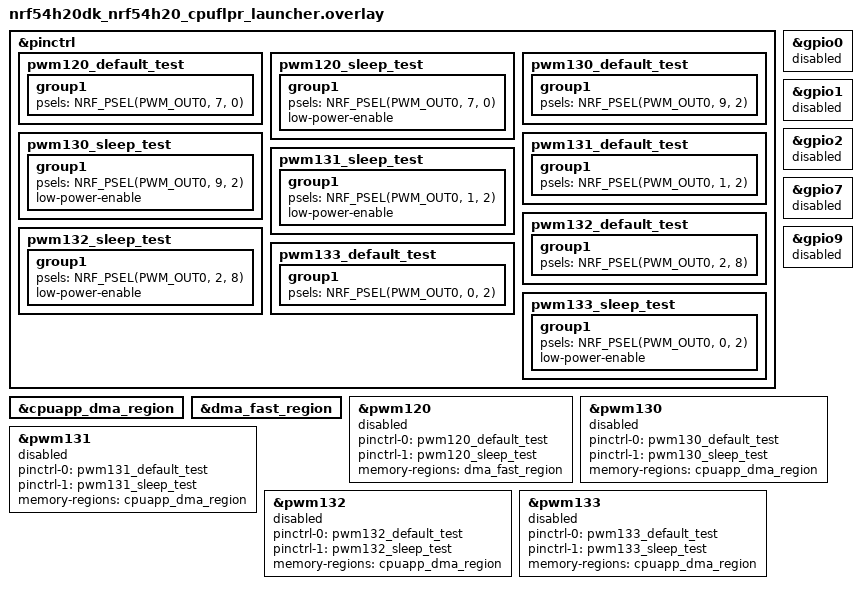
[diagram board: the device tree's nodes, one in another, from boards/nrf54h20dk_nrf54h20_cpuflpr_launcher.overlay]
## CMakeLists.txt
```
# SPDX-License-Identifier: LicenseRef-Nordic-5-Clause

cmake_minimum_required(VERSION 3.20.0)

find_package(Zephyr REQUIRED HINTS $ENV{ZEPHYR_BASE})
project(pwm_instances)

FILE(GLOB app_sources src/*.c)
target_sources(app PRIVATE ${app_sources})
```

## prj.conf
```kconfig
CONFIG_ZTEST=y
CONFIG_TEST_USERSPACE=y
CONFIG_PWM=y
CONFIG_LOG=y
```

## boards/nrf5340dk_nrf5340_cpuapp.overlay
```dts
/*
 * Copyright (c) 2026 Nordic Semiconductor ASA
 *
 * SPDX-License-Identifier: LicenseRef-Nordic-5-Clause
 */

&pinctrl {
	pwm0_default_test: pwm0_default_test {
		group1 {
			psels = <NRF_PSEL(PWM_OUT0, 0, 4)>;
		};
	};

	pwm0_sleep_test: pwm0_sleep_test {
		group1 {
			psels = <NRF_PSEL(PWM_OUT0, 0, 6)>;
			low-power-enable;
		};
	};

	pwm1_default_test: pwm1_default_test {
		group1 {
			psels = <NRF_PSEL(PWM_OUT0, 1, 4)>;
		};
	};

	pwm1_sleep_test: pwm1_sleep_test {
		group1 {
			psels = <NRF_PSEL(PWM_OUT0, 1, 4)>;
			low-power-enable;
		};
	};

	pwm2_default_test: pwm2_default_test {
		group1 {
			psels = <NRF_PSEL(PWM_OUT0, 1, 6)>;
		};
	};

	pwm2_sleep_test: pwm2_sleep_test {
		group1 {
			psels = <NRF_PSEL(PWM_OUT0, 1, 6)>;
			low-power-enable;
		};
	};

	pwm3_default_test: pwm3_default_test {
		group1 {
			psels = <NRF_PSEL(PWM_OUT0, 1, 8)>;
		};
	};

	pwm3_sleep_test: pwm3_sleep_test {
		group1 {
			psels = <NRF_PSEL(PWM_OUT0, 1, 8)>;
			low-power-enable;
		};
	};
};

&pwm0 {
	status = "okay";
	pinctrl-0 = <&pwm0_default_test>;
	pinctrl-1 = <&pwm0_sleep_test>;
	pinctrl-names = "default", "sleep";
};

&pwm1 {
	status = "okay";
	pinctrl-0 = <&pwm1_default_test>;
	pinctrl-1 = <&pwm1_sleep_test>;
	pinctrl-names = "default", "sleep";
};

&pwm2 {
	status = "okay";
	pinctrl-0 = <&pwm2_default_test>;
	pinctrl-1 = <&pwm2_sleep_test>;
	pinctrl-names = "default", "sleep";
};

&pwm3 {
	status = "okay";
	pinctrl-0 = <&pwm3_default_test>;
	pinctrl-1 = <&pwm3_sleep_test>;
	pinctrl-names = "default", "sleep";
};
```

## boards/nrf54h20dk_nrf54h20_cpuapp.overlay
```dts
/*
 * Copyright (c) 2025 Nordic Semiconductor ASA
 *
 * SPDX-License-Identifier: LicenseRef-Nordic-5-Clause
 */

&pinctrl {
	pwm120_default_test: pwm120_default_test {
		group1 {
			psels = <NRF_PSEL(PWM_OUT0, 7, 0)>;
		};
	};

	pwm120_sleep_test: pwm120_sleep_test {
		group1 {
			psels = <NRF_PSEL(PWM_OUT0, 7, 0)>;
			low-power-enable;
		};
	};

	pwm130_default_test: pwm130_default_test {
		group1 {
			psels = <NRF_PSEL(PWM_OUT0, 9, 2)>;
		};
	};

	pwm130_sleep_test: pwm130_sleep_test {
		group1 {
			psels = <NRF_PSEL(PWM_OUT0, 9, 2)>;
			low-power-enable;
		};
	};

	pwm131_default_test: pwm131_default_test {
		group1 {
			psels = <NRF_PSEL(PWM_OUT0, 1, 2)>;
		};
	};

	pwm131_sleep_test: pwm131_sleep_test {
		group1 {
			psels = <NRF_PSEL(PWM_OUT0, 1, 2)>;
			low-power-enable;
		};
	};

	pwm132_default_test: pwm132_default_test {
		group1 {
			psels = <NRF_PSEL(PWM_OUT0, 2, 8)>;
		};
	};

	pwm132_sleep_test: pwm132_sleep_test {
		group1 {
			psels = <NRF_PSEL(PWM_OUT0, 2, 8)>;
			low-power-enable;
		};
	};

	pwm133_default_test: pwm133_default_test {
		group1 {
			psels = <NRF_PSEL(PWM_OUT0, 0, 2)>;
		};
	};

	pwm133_sleep_test: pwm133_sleep_test {
		group1 {
			psels = <NRF_PSEL(PWM_OUT0, 0, 2)>;
			low-power-enable;
		};
	};
};

&pwm120 {
	status = "okay";
	pinctrl-0 = <&pwm120_default_test>;
	pinctrl-1 = <&pwm120_sleep_test>;
	pinctrl-names = "default", "sleep";
	memory-regions = <&dma_fast_region>;
};

&dma_fast_region {
	status = "okay";
};

&pwm130 {
	status = "okay";
	pinctrl-0 = <&pwm130_default_test>;
	pinctrl-1 = <&pwm130_sleep_test>;
	pinctrl-names = "default", "sleep";
	memory-regions = <&cpuapp_dma_region>;
};

&pwm131 {
	status = "okay";
	pinctrl-0 = <&pwm131_default_test>;
	pinctrl-1 = <&pwm131_sleep_test>;
	pinctrl-names = "default", "sleep";
	memory-regions = <&cpuapp_dma_region>;
};

&pwm132 {
	status = "okay";
	pinctrl-0 = <&pwm132_default_test>;
	pinctrl-1 = <&pwm132_sleep_test>;
	pinctrl-names = "default", "sleep";
	memory-regions = <&cpuapp_dma_region>;
};

&pwm133 {
	status = "okay";
	pinctrl-0 = <&pwm133_default_test>;
	pinctrl-1 = <&pwm133_sleep_test>;
	pinctrl-names = "default", "sleep";
	memory-regions = <&cpuapp_dma_region>;
};
```

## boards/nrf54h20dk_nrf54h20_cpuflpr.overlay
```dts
/*
 * Copyright (c) 2026 Nordic Semiconductor ASA
 *
 * SPDX-License-Identifier: LicenseRef-Nordic-5-Clause
 */

/*
 * Same PWM instances and pinout as nrf54h20dk_nrf54h20_cpuapp.overlay.
 * PWM120 uses dma_fast_region; PWM130–133 use cpuapp_dma_region (enabled below).
 */

&pinctrl {
	pwm120_default_test: pwm120_default_test {
		group1 {
			psels = <NRF_PSEL(PWM_OUT0, 7, 0)>;
		};
	};

	pwm120_sleep_test: pwm120_sleep_test {
		group1 {
			psels = <NRF_PSEL(PWM_OUT0, 7, 0)>;
			low-power-enable;
		};
	};

	pwm130_default_test: pwm130_default_test {
		group1 {
			psels = <NRF_PSEL(PWM_OUT0, 9, 2)>;
		};
	};

	pwm130_sleep_test: pwm130_sleep_test {
		group1 {
			psels = <NRF_PSEL(PWM_OUT0, 9, 2)>;
			low-power-enable;
		};
	};

	pwm131_default_test: pwm131_default_test {
		group1 {
			psels = <NRF_PSEL(PWM_OUT0, 1, 2)>;
		};
	};

	pwm131_sleep_test: pwm131_sleep_test {
		group1 {
			psels = <NRF_PSEL(PWM_OUT0, 1, 2)>;
			low-power-enable;
		};
	};

	pwm132_default_test: pwm132_default_test {
		group1 {
			psels = <NRF_PSEL(PWM_OUT0, 2, 8)>;
		};
	};

	pwm132_sleep_test: pwm132_sleep_test {
		group1 {
			psels = <NRF_PSEL(PWM_OUT0, 2, 8)>;
			low-power-enable;
		};
	};

	pwm133_default_test: pwm133_default_test {
		group1 {
			psels = <NRF_PSEL(PWM_OUT0, 0, 2)>;
		};
	};

	pwm133_sleep_test: pwm133_sleep_test {
		group1 {
			psels = <NRF_PSEL(PWM_OUT0, 0, 2)>;
			low-power-enable;
		};
	};
};

&cpuapp_dma_region {
	status = "okay";
};

&dma_fast_region {
	status = "okay";
};

&pwm120 {
	status = "okay";
	pinctrl-0 = <&pwm120_default_test>;
	pinctrl-1 = <&pwm120_sleep_test>;
	pinctrl-names = "default", "sleep";
	memory-regions = <&dma_fast_region>;
};

&pwm130 {
	status = "okay";
	pinctrl-0 = <&pwm130_default_test>;
	pinctrl-1 = <&pwm130_sleep_test>;
	pinctrl-names = "default", "sleep";
	memory-regions = <&cpuapp_dma_region>;
};

&pwm131 {
	status = "okay";
	pinctrl-0 = <&pwm131_default_test>;
	pinctrl-1 = <&pwm131_sleep_test>;
	pinctrl-names = "default", "sleep";
	memory-regions = <&cpuapp_dma_region>;
};

&pwm132 {
	status = "okay";
	pinctrl-0 = <&pwm132_default_test>;
	pinctrl-1 = <&pwm132_sleep_test>;
	pinctrl-names = "default", "sleep";
	memory-regions = <&cpuapp_dma_region>;
};

&pwm133 {
	status = "okay";
	pinctrl-0 = <&pwm133_default_test>;
	pinctrl-1 = <&pwm133_sleep_test>;
	pinctrl-names = "default", "sleep";
	memory-regions = <&cpuapp_dma_region>;
};
```

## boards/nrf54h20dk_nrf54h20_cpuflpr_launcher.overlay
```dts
/*
 * Copyright (c) 2026 Nordic Semiconductor ASA
 *
 * SPDX-License-Identifier: LicenseRef-Nordic-5-Clause
 */

/*
 * vpr_launcher (cpuapp): reserve all PWM instances and pads used by the FLPR
 * pwm_instances image (same mapping as cpuapp overlay).
 */

&pinctrl {
	pwm120_default_test: pwm120_default_test {
		group1 {
			psels = <NRF_PSEL(PWM_OUT0, 7, 0)>;
		};
	};

	pwm120_sleep_test: pwm120_sleep_test {
		group1 {
			psels = <NRF_PSEL(PWM_OUT0, 7, 0)>;
			low-power-enable;
		};
	};

	pwm130_default_test: pwm130_default_test {
		group1 {
			psels = <NRF_PSEL(PWM_OUT0, 9, 2)>;
		};
	};

	pwm130_sleep_test: pwm130_sleep_test {
		group1 {
			psels = <NRF_PSEL(PWM_OUT0, 9, 2)>;
			low-power-enable;
		};
	};

	pwm131_default_test: pwm131_default_test {
		group1 {
			psels = <NRF_PSEL(PWM_OUT0, 1, 2)>;
		};
	};

	pwm131_sleep_test: pwm131_sleep_test {
		group1 {
			psels = <NRF_PSEL(PWM_OUT0, 1, 2)>;
			low-power-enable;
		};
	};

	pwm132_default_test: pwm132_default_test {
		group1 {
			psels = <NRF_PSEL(PWM_OUT0, 2, 8)>;
		};
	};

	pwm132_sleep_test: pwm132_sleep_test {
		group1 {
			psels = <NRF_PSEL(PWM_OUT0, 2, 8)>;
			low-power-enable;
		};
	};

	pwm133_default_test: pwm133_default_test {
		group1 {
			psels = <NRF_PSEL(PWM_OUT0, 0, 2)>;
		};
	};

	pwm133_sleep_test: pwm133_sleep_test {
		group1 {
			psels = <NRF_PSEL(PWM_OUT0, 0, 2)>;
			low-power-enable;
		};
	};
};

&gpio0 {
	status = "reserved";
};

&gpio1 {
	status = "reserved";
};

&gpio2 {
	status = "reserved";
};

&gpio7 {
	status = "reserved";
};

&gpio9 {
	status = "reserved";
};

&cpuapp_dma_region {
	status = "okay";
};

&dma_fast_region {
	status = "okay";
};

&pwm120 {
	status = "reserved";
	pinctrl-0 = <&pwm120_default_test>;
	pinctrl-1 = <&pwm120_sleep_test>;
	pinctrl-names = "default", "sleep";
	memory-regions = <&dma_fast_region>;
};

&pwm130 {
	status = "reserved";
	pinctrl-0 = <&pwm130_default_test>;
	pinctrl-1 = <&pwm130_sleep_test>;
	pinctrl-names = "default", "sleep";
	memory-regions = <&cpuapp_dma_region>;
};

&pwm131 {
	status = "reserved";
	pinctrl-0 = <&pwm131_default_test>;
	pinctrl-1 = <&pwm131_sleep_test>;
	pinctrl-names = "default", "sleep";
	memory-regions = <&cpuapp_dma_region>;
};

&pwm132 {
	status = "reserved";
	pinctrl-0 = <&pwm132_default_test>;
	pinctrl-1 = <&pwm132_sleep_test>;
	pinctrl-names = "default", "sleep";
	memory-regions = <&cpuapp_dma_region>;
};

&pwm133 {
	status = "reserved";
	pinctrl-0 = <&pwm133_default_test>;
	pinctrl-1 = <&pwm133_sleep_test>;
	pinctrl-names = "default", "sleep";
	memory-regions = <&cpuapp_dma_region>;
};
```

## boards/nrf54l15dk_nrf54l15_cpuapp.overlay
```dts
/*
 * Copyright (c) 2025 Nordic Semiconductor ASA
 *
 * SPDX-License-Identifier: LicenseRef-Nordic-5-Clause
 */

&pinctrl {
	pwm20_default_test: pwm20_default_test {
		group1 {
			psels = <NRF_PSEL(PWM_OUT0, 1, 10)>;
		};
	};

	pwm20_sleep_test: pwm20_sleep_test {
		group1 {
			psels = <NRF_PSEL(PWM_OUT0, 1, 10)>;
			low-power-enable;
		};
	};

	pwm21_default_test: pwm21_default_test {
		group1 {
			psels = <NRF_PSEL(PWM_OUT0, 1, 12)>;
		};
	};

	pwm21_sleep_test: pwm21_sleep_test {
		group1 {
			psels = <NRF_PSEL(PWM_OUT0, 1, 12)>;
			low-power-enable;
		};
	};

	pwm22_default_test: pwm22_default_test {
		group1 {
			psels = <NRF_PSEL(PWM_OUT0, 1, 14)>;
		};
	};

	pwm22_sleep_test: pwm22_sleep_test {
		group1 {
			psels = <NRF_PSEL(PWM_OUT0, 1, 14)>;
			low-power-enable;
		};
	};
};

&pwm20 {
	status = "okay";
	pinctrl-0 = <&pwm20_default_test>;
	pinctrl-1 = <&pwm20_sleep_test>;
	pinctrl-names = "default", "sleep";
};

&pwm21 {
	status = "okay";
	pinctrl-0 = <&pwm21_default_test>;
	pinctrl-1 = <&pwm21_sleep_test>;
	pinctrl-names = "default", "sleep";
};

&pwm22 {
	status = "okay";
	pinctrl-0 = <&pwm22_default_test>;
	pinctrl-1 = <&pwm22_sleep_test>;
	pinctrl-names = "default", "sleep";
};
```

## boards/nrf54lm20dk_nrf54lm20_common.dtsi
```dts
/*
 * Copyright (c) 2026 Nordic Semiconductor ASA
 *
 * SPDX-License-Identifier: LicenseRef-Nordic-5-Clause
 */

&pinctrl {
	pwm20_default_test: pwm20_default_test {
		group1 {
			psels = <NRF_PSEL(PWM_OUT0, 1, 22)>;
		};
	};

	pwm20_sleep_test: pwm20_sleep_test {
		group1 {
			psels = <NRF_PSEL(PWM_OUT0, 1, 22)>;
			low-power-enable;
		};
	};

	pwm21_default_test: pwm21_default_test {
		group1 {
			psels = <NRF_PSEL(PWM_OUT0, 1, 25)>;
		};
	};

	pwm21_sleep_test: pwm21_sleep_test {
		group1 {
			psels = <NRF_PSEL(PWM_OUT0, 1, 25)>;
			low-power-enable;
		};
	};

	pwm22_default_test: pwm22_default_test {
		group1 {
			psels = <NRF_PSEL(PWM_OUT0, 1, 27)>;
		};
	};

	pwm22_sleep_test: pwm22_sleep_test {
		group1 {
			psels = <NRF_PSEL(PWM_OUT0, 1, 27)>;
			low-power-enable;
		};
	};
};

&pwm20 {
	status = "okay";
	pinctrl-0 = <&pwm20_default_test>;
	pinctrl-1 = <&pwm20_sleep_test>;
	pinctrl-names = "default", "sleep";
};

&pwm21 {
	status = "okay";
	pinctrl-0 = <&pwm21_default_test>;
	pinctrl-1 = <&pwm21_sleep_test>;
	pinctrl-names = "default", "sleep";
};

&pwm22 {
	status = "okay";
	pinctrl-0 = <&pwm22_default_test>;
	pinctrl-1 = <&pwm22_sleep_test>;
	pinctrl-names = "default", "sleep";
};
```

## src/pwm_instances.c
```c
/*
 * Copyright (c) 2025, Nordic Semiconductor ASA
 *
 * SPDX-License-Identifier: LicenseRef-Nordic-5-Clause
 */

#include <zephyr/kernel.h>
#include <zephyr/drivers/pwm.h>
#include <zephyr/ztest.h>

#include <zephyr/logging/log.h>
LOG_MODULE_REGISTER(test);

#define DEVICE_DT_GET_AND_COMMA(node_id) DEVICE_DT_GET(node_id),
/* Generate a list of devices for all instances of the "compat" */
#define DEVS_FOR_DT_COMPAT(compat) \
	DT_FOREACH_STATUS_OKAY(compat, DEVICE_DT_GET_AND_COMMA)

static const struct device *const devices[] = {
#ifdef CONFIG_PWM_NRFX
	DEVS_FOR_DT_COMPAT(nordic_nrf_pwm)
#endif
};

typedef void (*test_func_t)(const struct device *dev);
typedef bool (*capability_func_t)(const struct device *dev);

static void setup_instance(const struct device *dev)
{
	/* Left for future test expansion. */
}

static void tear_down_instance(const struct device *dev)
{
	/* Left for future test expansion. */
}

static void test_all_instances(test_func_t func, capability_func_t capability_check)
{
	int devices_skipped = 0;

	zassert_true(ARRAY_SIZE(devices) > 0, "No device found");
	for (int i = 0; i < ARRAY_SIZE(devices); i++) {
		setup_instance(devices[i]);
		TC_PRINT("\nInstance %u: ", i + 1);
		if ((capability_check == NULL) ||
		     capability_check(devices[i])) {
			TC_PRINT("Testing %s\n", devices[i]->name);
			func(devices[i]);
		} else {
			TC_PRINT("Skipped for %s\n", devices[i]->name);
			devices_skipped++;
		}
		tear_down_instance(devices[i]);
		/* Allow logs to be printed. */
		k_sleep(K_MSEC(100));
	}
	if (devices_skipped == ARRAY_SIZE(devices)) {
		ztest_test_skip();
	}
}


/**
 * Confirm that instance can be configured to output PWM signal
 */
static void test_pwm_set_cycles_instance(const struct device *dev)
{
	int ret;

	for (int i = 1; i < 21; i++) {
		ret = pwm_set_cycles(dev, 0, 32000, i * 500, 0);
		zassert_equal(0, ret, "%s: pwm_set_cycles() has failed: %d\n", dev->name, ret);
		k_msleep(50);
	}
}

static bool test_pwm_set_cycles_capable(const struct device *dev)
{
	return true;
}

ZTEST(pwm_instances, test_pwm_set_cycles)
{
	test_all_instances(test_pwm_set_cycles_instance, test_pwm_set_cycles_capable);
}

static void *suite_setup(void)
{
	int i;

	for (i = 0; i < ARRAY_SIZE(devices); i++) {
		zassert_true(device_is_ready(devices[i]),
			     "Device %s is not ready", devices[i]->name);
		k_object_access_grant(devices[i], k_current_get());
	}

	return NULL;
}

ZTEST_SUITE(pwm_instances, NULL, suite_setup, NULL, NULL, NULL);
```
